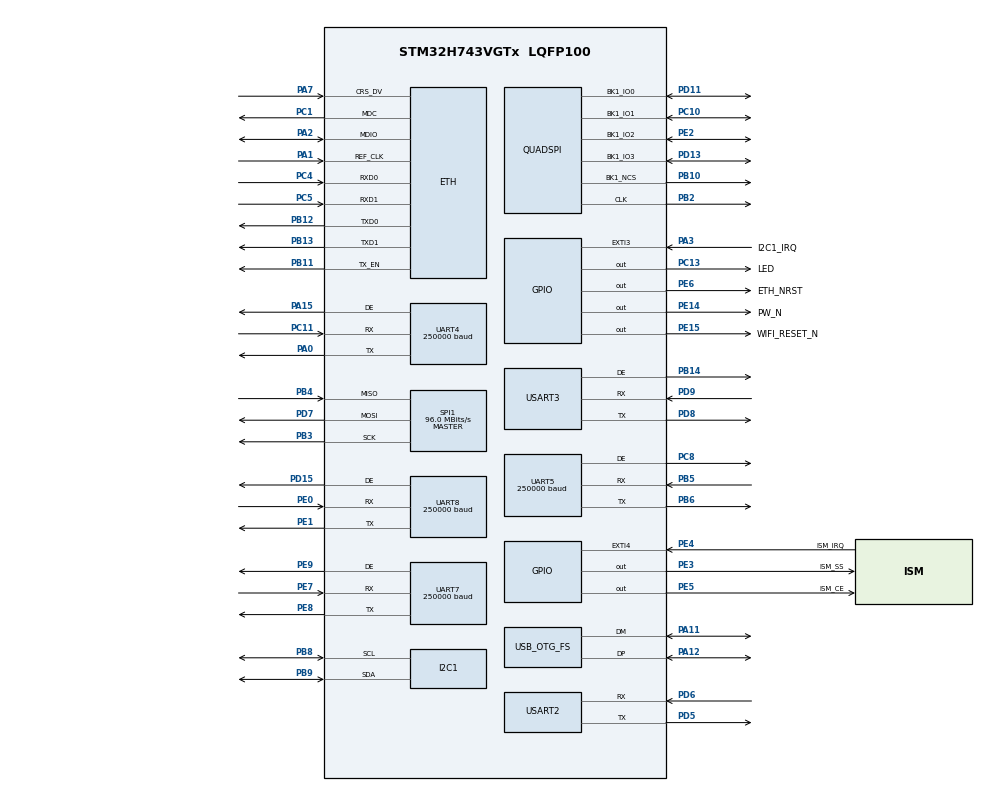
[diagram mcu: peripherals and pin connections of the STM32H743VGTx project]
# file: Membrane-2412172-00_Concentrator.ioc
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Dma.Request0=UART4_TX
Dma.Request1=UART5_TX
Dma.Request2=UART7_TX
Dma.Request3=UART8_TX
Dma.Request4=USART2_TX
Dma.UART4_TX.0.Direction=DMA_MEMORY_TO_PERIPH
Dma.UART4_TX.0.EventEnable=DISABLE
Dma.UART4_TX.0.FIFOMode=DMA_FIFOMODE_DISABLE
Dma.UART4_TX.0.Instance=DMA1_Stream0
Dma.UART4_TX.0.MemDataAlignment=DMA_MDATAALIGN_BYTE
Dma.UART4_TX.0.MemInc=DMA_MINC_ENABLE
Dma.UART4_TX.0.Mode=DMA_NORMAL
Dma.UART4_TX.0.PeriphDataAlignment=DMA_PDATAALIGN_BYTE
Dma.UART4_TX.0.PeriphInc=DMA_PINC_DISABLE
Dma.UART4_TX.0.Polarity=HAL_DMAMUX_REQ_GEN_RISING
Dma.UART4_TX.0.Priority=DMA_PRIORITY_LOW
Dma.UART4_TX.0.RequestNumber=1
Dma.UART4_TX.0.SignalID=NONE
Dma.UART4_TX.0.SyncEnable=DISABLE
Dma.UART4_TX.0.SyncPolarity=HAL_DMAMUX_SYNC_NO_EVENT
Dma.UART4_TX.0.SyncRequestNumber=1
Dma.UART4_TX.0.SyncSignalID=NONE
Dma.UART5_TX.1.Direction=DMA_MEMORY_TO_PERIPH
Dma.UART5_TX.1.EventEnable=DISABLE
Dma.UART5_TX.1.FIFOMode=DMA_FIFOMODE_DISABLE
Dma.UART5_TX.1.Instance=DMA1_Stream1
Dma.UART5_TX.1.MemDataAlignment=DMA_MDATAALIGN_BYTE
Dma.UART5_TX.1.MemInc=DMA_MINC_ENABLE
Dma.UART5_TX.1.Mode=DMA_NORMAL
Dma.UART5_TX.1.PeriphDataAlignment=DMA_PDATAALIGN_BYTE
Dma.UART5_TX.1.PeriphInc=DMA_PINC_DISABLE
Dma.UART5_TX.1.Polarity=HAL_DMAMUX_REQ_GEN_RISING
Dma.UART5_TX.1.Priority=DMA_PRIORITY_LOW
Dma.UART5_TX.1.RequestNumber=1
Dma.UART5_TX.1.SignalID=NONE
Dma.UART5_TX.1.SyncEnable=DISABLE
Dma.UART5_TX.1.SyncPolarity=HAL_DMAMUX_SYNC_NO_EVENT
Dma.UART5_TX.1.SyncRequestNumber=1
Dma.UART5_TX.1.SyncSignalID=NONE
Dma.UART7_TX.2.Direction=DMA_MEMORY_TO_PERIPH
Dma.UART7_TX.2.EventEnable=DISABLE
Dma.UART7_TX.2.FIFOMode=DMA_FIFOMODE_DISABLE
Dma.UART7_TX.2.Instance=DMA1_Stream2
Dma.UART7_TX.2.MemDataAlignment=DMA_MDATAALIGN_BYTE
Dma.UART7_TX.2.MemInc=DMA_MINC_ENABLE
Dma.UART7_TX.2.Mode=DMA_NORMAL
Dma.UART7_TX.2.PeriphDataAlignment=DMA_PDATAALIGN_BYTE
Dma.UART7_TX.2.PeriphInc=DMA_PINC_DISABLE
Dma.UART7_TX.2.Polarity=HAL_DMAMUX_REQ_GEN_RISING
Dma.UART7_TX.2.Priority=DMA_PRIORITY_LOW
Dma.UART7_TX.2.RequestNumber=1
Dma.UART7_TX.2.SignalID=NONE
Dma.UART7_TX.2.SyncEnable=DISABLE
Dma.UART7_TX.2.SyncPolarity=HAL_DMAMUX_SYNC_NO_EVENT
Dma.UART7_TX.2.SyncRequestNumber=1
Dma.UART7_TX.2.SyncSignalID=NONE
Dma.UART8_TX.3.Direction=DMA_MEMORY_TO_PERIPH
Dma.UART8_TX.3.EventEnable=DISABLE
Dma.UART8_TX.3.FIFOMode=DMA_FIFOMODE_DISABLE
Dma.UART8_TX.3.Instance=DMA1_Stream3
Dma.UART8_TX.3.MemDataAlignment=DMA_MDATAALIGN_BYTE
Dma.UART8_TX.3.MemInc=DMA_MINC_ENABLE
Dma.UART8_TX.3.Mode=DMA_NORMAL
Dma.UART8_TX.3.PeriphDataAlignment=DMA_PDATAALIGN_BYTE
Dma.UART8_TX.3.PeriphInc=DMA_PINC_DISABLE
Dma.UART8_TX.3.Polarity=HAL_DMAMUX_REQ_GEN_RISING
Dma.UART8_TX.3.Priority=DMA_PRIORITY_LOW
Dma.UART8_TX.3.RequestNumber=1
Dma.UART8_TX.3.SignalID=NONE
Dma.UART8_TX.3.SyncEnable=DISABLE
Dma.UART8_TX.3.SyncPolarity=HAL_DMAMUX_SYNC_NO_EVENT
Dma.UART8_TX.3.SyncRequestNumber=1
Dma.UART8_TX.3.SyncSignalID=NONE
Dma.USART2_TX.4.Direction=DMA_MEMORY_TO_PERIPH
Dma.USART2_TX.4.EventEnable=DISABLE
Dma.USART2_TX.4.FIFOMode=DMA_FIFOMODE_DISABLE
Dma.USART2_TX.4.Instance=DMA1_Stream4
Dma.USART2_TX.4.MemDataAlignment=DMA_MDATAALIGN_BYTE
Dma.USART2_TX.4.MemInc=DMA_MINC_ENABLE
Dma.USART2_TX.4.Mode=DMA_NORMAL
Dma.USART2_TX.4.PeriphDataAlignment=DMA_PDATAALIGN_BYTE
Dma.USART2_TX.4.PeriphInc=DMA_PINC_DISABLE
Dma.USART2_TX.4.Polarity=HAL_DMAMUX_REQ_GEN_RISING
Dma.USART2_TX.4.Priority=DMA_PRIORITY_LOW
Dma.USART2_TX.4.RequestNumber=1
Dma.USART2_TX.4.SignalID=NONE
Dma.USART2_TX.4.SyncEnable=DISABLE
Dma.USART2_TX.4.SyncPolarity=HAL_DMAMUX_SYNC_NO_EVENT
Dma.USART2_TX.4.SyncRequestNumber=1
Dma.USART2_TX.4.SyncSignalID=NONE
ETH.MediaInterface=HAL_ETH_RMII_MODE
I2C1.Timing=0x307075B1
Mcu.Family=STM32H7
Mcu.Name=STM32H743VGTx
Mcu.Package=LQFP100
NVIC.DMA1_Stream0_IRQn=true\:0\:0\:false\:false\:true\:false\:true\:true
NVIC.DMA1_Stream1_IRQn=true\:0\:0\:false\:false\:true\:false\:true\:true
NVIC.DMA1_Stream2_IRQn=true\:0\:0\:false\:false\:true\:false\:true\:true
NVIC.DMA1_Stream3_IRQn=true\:0\:0\:false\:false\:true\:false\:true\:true
NVIC.DMA1_Stream4_IRQn=true\:0\:0\:false\:false\:true\:false\:true\:true
NVIC.OTG_FS_IRQn=true\:0\:0\:false\:false\:true\:false\:true\:true
NVIC.PriorityGroup=NVIC_PRIORITYGROUP_4
NVIC.UART4_IRQn=true\:0\:0\:false\:false\:true\:true\:true\:true
NVIC.UART5_IRQn=true\:0\:0\:false\:false\:true\:true\:true\:true
NVIC.UART7_IRQn=true\:0\:0\:false\:false\:true\:true\:true\:true
NVIC.UART8_IRQn=true\:0\:0\:false\:false\:true\:true\:true\:true
NVIC.USART2_IRQn=true\:0\:0\:false\:false\:true\:true\:true\:true
PA0.Mode=Asynchronous
PA0.Signal=UART4_TX
PA1.GPIO_Speed=GPIO_SPEED_FREQ_VERY_HIGH
PA1.Mode=RMII
PA1.Signal=ETH_REF_CLK
PA11.Mode=Device_Only
PA11.Signal=USB_OTG_FS_DM
PA12.Mode=Device_Only
PA12.Signal=USB_OTG_FS_DP
PA13\ (JTMS/SWDIO).Mode=Serial_Wire
PA13\ (JTMS/SWDIO).Signal=DEBUG_JTMS-SWDIO
PA14\ (JTCK/SWCLK).Mode=Serial_Wire
PA14\ (JTCK/SWCLK).Signal=DEBUG_JTCK-SWCLK
PA15\ (JTDI).Mode=Hardware Flow Control (RS485)
PA15\ (JTDI).Signal=UART4_DE
PA2.GPIO_Speed=GPIO_SPEED_FREQ_VERY_HIGH
PA2.Mode=RMII
PA2.Signal=ETH_MDIO
PA3.GPIO_Label=I2C1_IRQ
PA3.Signal=GPXTI3
PA7.GPIO_Speed=GPIO_SPEED_FREQ_VERY_HIGH
PA7.Mode=RMII
PA7.Signal=ETH_CRS_DV
PB10.GPIO_Speed=GPIO_SPEED_FREQ_VERY_HIGH
PB10.Mode=Single Bank 1
PB10.Signal=QUADSPI_BK1_NCS
PB11.GPIO_Speed=GPIO_SPEED_FREQ_VERY_HIGH
PB11.Mode=RMII
PB11.Signal=ETH_TX_EN
PB12.GPIO_Speed=GPIO_SPEED_FREQ_VERY_HIGH
PB12.Mode=RMII
PB12.Signal=ETH_TXD0
PB13.GPIO_Speed=GPIO_SPEED_FREQ_VERY_HIGH
PB13.Mode=RMII
PB13.Signal=ETH_TXD1
PB14.Mode=Hardware Flow Control (RS485)
PB14.Signal=USART3_DE
PB2.GPIO_Speed=GPIO_SPEED_FREQ_VERY_HIGH
PB2.Mode=Single Bank 1
PB2.Signal=QUADSPI_CLK
PB3\ (JTDO/TRACESWO).Mode=Full_Duplex_Master
PB3\ (JTDO/TRACESWO).Signal=SPI1_SCK
PB4\ (NJTRST).Mode=Full_Duplex_Master
PB4\ (NJTRST).Signal=SPI1_MISO
PB5.Mode=Asynchronous
PB5.Signal=UART5_RX
PB6.Mode=Asynchronous
PB6.Signal=UART5_TX
PB8.Mode=I2C
PB8.Signal=I2C1_SCL
PB9.Mode=I2C
PB9.Signal=I2C1_SDA
PC1.GPIO_Speed=GPIO_SPEED_FREQ_VERY_HIGH
PC1.Mode=RMII
PC1.Signal=ETH_MDC
PC10.GPIO_Speed=GPIO_SPEED_FREQ_VERY_HIGH
PC10.Mode=Single Bank 1
PC10.Signal=QUADSPI_BK1_IO1
PC11.Mode=Asynchronous
PC11.Signal=UART4_RX
PC13.GPIO_Label=LED
PC13.Signal=GPIO_Output
PC4.GPIO_Speed=GPIO_SPEED_FREQ_VERY_HIGH
PC4.Mode=RMII
PC4.Signal=ETH_RXD0
PC5.GPIO_Speed=GPIO_SPEED_FREQ_VERY_HIGH
PC5.Mode=RMII
PC5.Signal=ETH_RXD1
PC8.Mode=Hardware Flow Control (RS485)
PC8.Signal=UART5_DE
PD11.GPIO_Speed=GPIO_SPEED_FREQ_VERY_HIGH
PD11.Mode=Single Bank 1
PD11.Signal=QUADSPI_BK1_IO0
PD13.GPIO_Speed=GPIO_SPEED_FREQ_VERY_HIGH
PD13.Mode=Single Bank 1
PD13.Signal=QUADSPI_BK1_IO3
PD15.Mode=Hardware Flow Control (RS485)
PD15.Signal=UART8_DE
PD5.GPIO_PuPd=GPIO_PULLUP
PD5.GPIO_Speed=GPIO_SPEED_FREQ_HIGH
PD5.Mode=Asynchronous
PD5.Signal=USART2_TX
PD6.GPIO_PuPd=GPIO_PULLUP
PD6.GPIO_Speed=GPIO_SPEED_FREQ_HIGH
PD6.Mode=Asynchronous
PD6.Signal=USART2_RX
PD7.Mode=Full_Duplex_Master
PD7.Signal=SPI1_MOSI
PD8.Mode=Asynchronous
PD8.Signal=USART3_TX
PD9.Mode=Asynchronous
PD9.Signal=USART3_RX
PE0.Mode=Asynchronous
PE0.Signal=UART8_RX
PE1.Mode=Asynchronous
PE1.Signal=UART8_TX
PE14.GPIO_Label=PW_N
PE14.PinState=GPIO_PIN_SET
PE14.Signal=GPIO_Output
PE15.GPIO_Label=WIFI_RESET_N
PE15.GPIO_ModeDefaultOutputPP=GPIO_MODE_OUTPUT_OD
PE15.GPIO_PuPd=GPIO_NOPULL
PE15.PinState=GPIO_PIN_SET
PE15.Signal=GPIO_Output
PE2.GPIO_Speed=GPIO_SPEED_FREQ_VERY_HIGH
PE2.Mode=Single Bank 1
PE2.Signal=QUADSPI_BK1_IO2
PE3.GPIO_Label=ISM_SS
PE3.PinState=GPIO_PIN_SET
PE3.Signal=GPIO_Output
PE4.GPIO_Label=ISM_IRQ
PE4.Signal=GPXTI4
PE5.GPIO_Label=ISM_CE
PE5.PinState=GPIO_PIN_SET
PE5.Signal=GPIO_Output
PE6.GPIO_Label=ETH_NRST
PE6.PinState=GPIO_PIN_SET
PE6.Signal=GPIO_Output
PE7.Mode=Asynchronous
PE7.Signal=UART7_RX
PE8.Mode=Asynchronous
PE8.Signal=UART7_TX
PE9.Mode=Hardware Flow Control (RS485)
PE9.Signal=UART7_DE
ProjectManager.HeapSize=0x200
ProjectManager.StackSize=0x400
ProjectManager.TargetToolchain=STM32CubeIDE
QUADSPI.ClockPrescaler=1
QUADSPI.FlashSize=23
RCC.ADCFreq_Value=100000000
RCC.APB1Freq_Value=120000000
RCC.APB2Freq_Value=120000000
RCC.APB3Freq_Value=120000000
RCC.APB4Freq_Value=120000000
RCC.CortexFreq_Value=480000000
RCC.D1PPRE=RCC_APB3_DIV2
RCC.D2PPRE1=RCC_APB1_DIV2
RCC.D2PPRE2=RCC_APB2_DIV2
RCC.D3PPRE=RCC_APB4_DIV2
RCC.DIVM1=4
RCC.DIVN1=60
RCC.DIVN2=100
RCC.DIVQ1=5
RCC.DIVR2=4
RCC.HCLKFreq_Value=240000000
RCC.HPRE=RCC_HCLK_DIV2
RCC.PLL2FRACN=0
RCC.PLL3FRACN=0
RCC.PLLFRACN=0
RCC.QSPICLockSelection=RCC_QSPICLKSOURCE_PLL2
RCC.SYSCLKFreq_VALUE=480000000
RCC.SYSCLKSource=RCC_SYSCLKSOURCE_PLLCLK
RCC.USART234578CLockSelection=RCC_USART234578CLKSOURCE_CSI
RCC.USBCLockSelection=RCC_USBCLKSOURCE_HSI48
RCC.USBFreq_Value=48000000
SPI1.BaudRatePrescaler=SPI_BAUDRATEPRESCALER_2
SPI1.CalculateBaudRate=96.0 MBits/s
SPI1.Direction=SPI_DIRECTION_2LINES
SPI1.Mode=SPI_MODE_MASTER
SPI1.VirtualType=VM_MASTER
UART4.BaudRate=250000
UART5.BaudRate=250000
UART7.BaudRate=250000
UART8.BaudRate=250000
USART2.DataInvertParam=ADVFEATURE_DATAINV_DISABLE
USART2.FIFOMode=FIFOMODE_ENABLE
USART2.RXFIFOThreshold=RXFIFO_THRESHOLD_HALFFULL
USART2.SwapParam=ADVFEATURE_SWAP_ENABLE
USART2.TXFIFOThreshold=TXFIFO_THRESHOLD_HALFFULL
USART2.VirtualMode-Asynchronous=VM_ASYNC
USART3.VirtualMode-Asynchronous=VM_ASYNC
USART3.VirtualMode-Hardware\ Flow\ Control\ (RS485)=VM_ASYNC
USB_DEVICE.CLASS_NAME_FS=CDC
USB_DEVICE.VirtualMode-CDC_FS=Cdc
USB_DEVICE.VirtualModeFS=Cdc_FS
USB_OTG_FS.VirtualMode=Device_Only
VP_CRC_VS_CRC.Mode=CRC_Activate
VP_USB_DEVICE_VS_USB_DEVICE_CDC_FS.Mode=CDC_FS
board=custom

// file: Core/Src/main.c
/* USER CODE BEGIN Header */
/**
  ******************************************************************************
  * @file           : main.c
  * @brief          : Main program body
  ******************************************************************************
  * @attention
  *
  * Copyright (c) 2024 STMicroelectronics.
  * All rights reserved.
  *
  * This software is licensed under terms that can be found in the LICENSE file
  * in the root directory of this software component.
  * If no LICENSE file comes with this software, it is provided AS-IS.
  *
  ******************************************************************************
  */
/* USER CODE END Header */
#include "main.h"
#include "string.h"
#include "usb_device.h"

#if defined ( __ICCARM__ ) /*!< IAR Compiler */
#pragma location=0x30000000
ETH_DMADescTypeDef  DMARxDscrTab[ETH_RX_DESC_CNT]; /* Ethernet Rx DMA Descriptors */
#pragma location=0x30000080
ETH_DMADescTypeDef  DMATxDscrTab[ETH_TX_DESC_CNT]; /* Ethernet Tx DMA Descriptors */

#elif defined ( __CC_ARM )  /* MDK ARM Compiler */

__attribute__((at(0x30000000))) ETH_DMADescTypeDef  DMARxDscrTab[ETH_RX_DESC_CNT]; /* Ethernet Rx DMA Descriptors */
__attribute__((at(0x30000080))) ETH_DMADescTypeDef  DMATxDscrTab[ETH_TX_DESC_CNT]; /* Ethernet Tx DMA Descriptors */

#elif defined ( __GNUC__ ) /* GNU Compiler */

ETH_DMADescTypeDef DMARxDscrTab[ETH_RX_DESC_CNT] __attribute__((section(".RxDecripSection"))); /* Ethernet Rx DMA Descriptors */
ETH_DMADescTypeDef DMATxDscrTab[ETH_TX_DESC_CNT] __attribute__((section(".TxDecripSection")));   /* Ethernet Tx DMA Descriptors */
#endif

ETH_TxPacketConfig TxConfig;

CRC_HandleTypeDef hcrc;

ETH_HandleTypeDef heth;

I2C_HandleTypeDef hi2c1;

QSPI_HandleTypeDef hqspi;

SPI_HandleTypeDef hspi1;

UART_HandleTypeDef huart4;
UART_HandleTypeDef huart5;
UART_HandleTypeDef huart7;
UART_HandleTypeDef huart8;
UART_HandleTypeDef huart2;
UART_HandleTypeDef huart3;
DMA_HandleTypeDef hdma_uart4_tx;
DMA_HandleTypeDef hdma_uart5_tx;
DMA_HandleTypeDef hdma_uart7_tx;
DMA_HandleTypeDef hdma_uart8_tx;
DMA_HandleTypeDef hdma_usart2_tx;

void SystemClock_Config(void);
static void MX_GPIO_Init(void);
static void MX_DMA_Init(void);
static void MX_I2C1_Init(void);
static void MX_QUADSPI_Init(void);
static void MX_UART4_Init(void);
static void MX_UART5_Init(void);
static void MX_UART7_Init(void);
static void MX_UART8_Init(void);
static void MX_USART2_UART_Init(void);
static void MX_USART3_UART_Init(void);
static void MX_SPI1_Init(void);
static void MX_CRC_Init(void);
static void MX_ETH_Init(void);

int main(void)
{

  /* MCU Configuration--------------------------------------------------------*/

  /* Reset of all peripherals, Initializes the Flash interface and the Systick. */
  HAL_Init();

  /* Configure the system clock */
  SystemClock_Config();

  /* USER CODE BEGIN SysInit */
  A_init_mem();

  /* USER CODE END SysInit */

  /* Initialize all configured peripherals */
  MX_GPIO_Init();
  MX_DMA_Init();
  MX_I2C1_Init();
  MX_QUADSPI_Init();
  MX_UART4_Init();
  MX_UART5_Init();
  MX_UART7_Init();
  MX_UART8_Init();
  MX_USART2_UART_Init();
  MX_USART3_UART_Init();
  MX_SPI1_Init();
  MX_CRC_Init();
  MX_ETH_Init();
  MX_USB_DEVICE_Init();
  /* USER CODE BEGIN 2 */
  A_start();

  /* USER CODE END 2 */

  /* Infinite loop */
  while (1)
  {

  }
}

void SystemClock_Config(void)
{
  RCC_OscInitTypeDef RCC_OscInitStruct = {0};
  RCC_ClkInitTypeDef RCC_ClkInitStruct = {0};

  /** Supply configuration update enable
  */
  HAL_PWREx_ConfigSupply(PWR_LDO_SUPPLY);

  /** Configure the main internal regulator output voltage
  */
  __HAL_PWR_VOLTAGESCALING_CONFIG(PWR_REGULATOR_VOLTAGE_SCALE1);

  while(!__HAL_PWR_GET_FLAG(PWR_FLAG_VOSRDY)) {}

  __HAL_RCC_SYSCFG_CLK_ENABLE();
  __HAL_PWR_VOLTAGESCALING_CONFIG(PWR_REGULATOR_VOLTAGE_SCALE0);

  while(!__HAL_PWR_GET_FLAG(PWR_FLAG_VOSRDY)) {}

  /** Initializes the RCC Oscillators according to the specified parameters
  * in the RCC_OscInitTypeDef structure.
  */
  RCC_OscInitStruct.OscillatorType = RCC_OSCILLATORTYPE_HSI48|RCC_OSCILLATORTYPE_CSI
                              |RCC_OSCILLATORTYPE_HSI;
  RCC_OscInitStruct.HSIState = RCC_HSI_DIV1;
  RCC_OscInitStruct.HSICalibrationValue = RCC_HSICALIBRATION_DEFAULT;
  RCC_OscInitStruct.HSI48State = RCC_HSI48_ON;
  RCC_OscInitStruct.CSIState = RCC_CSI_ON;
  RCC_OscInitStruct.CSICalibrationValue = RCC_CSICALIBRATION_DEFAULT;
  RCC_OscInitStruct.PLL.PLLState = RCC_PLL_ON;
  RCC_OscInitStruct.PLL.PLLSource = RCC_PLLSOURCE_HSI;
  RCC_OscInitStruct.PLL.PLLM = 4;
  RCC_OscInitStruct.PLL.PLLN = 60;
  RCC_OscInitStruct.PLL.PLLP = 2;
  RCC_OscInitStruct.PLL.PLLQ = 5;
  RCC_OscInitStruct.PLL.PLLR = 2;
  RCC_OscInitStruct.PLL.PLLRGE = RCC_PLL1VCIRANGE_3;
  RCC_OscInitStruct.PLL.PLLVCOSEL = RCC_PLL1VCOWIDE;
  RCC_OscInitStruct.PLL.PLLFRACN = 0;
  if (HAL_RCC_OscConfig(&RCC_OscInitStruct) != HAL_OK)
  {
    Error_Handler();
  }

  /** Initializes the CPU, AHB and APB buses clocks
  */
  RCC_ClkInitStruct.ClockType = RCC_CLOCKTYPE_HCLK|RCC_CLOCKTYPE_SYSCLK
                              |RCC_CLOCKTYPE_PCLK1|RCC_CLOCKTYPE_PCLK2
                              |RCC_CLOCKTYPE_D3PCLK1|RCC_CLOCKTYPE_D1PCLK1;
  RCC_ClkInitStruct.SYSCLKSource = RCC_SYSCLKSOURCE_PLLCLK;
  RCC_ClkInitStruct.SYSCLKDivider = RCC_SYSCLK_DIV1;
  RCC_ClkInitStruct.AHBCLKDivider = RCC_HCLK_DIV2;
  RCC_ClkInitStruct.APB3CLKDivider = RCC_APB3_DIV2;
  RCC_ClkInitStruct.APB1CLKDivider = RCC_APB1_DIV2;
  RCC_ClkInitStruct.APB2CLKDivider = RCC_APB2_DIV2;
  RCC_ClkInitStruct.APB4CLKDivider = RCC_APB4_DIV2;

  if (HAL_RCC_ClockConfig(&RCC_ClkInitStruct, FLASH_LATENCY_4) != HAL_OK)
  {
    Error_Handler();
  }
}

static void MX_CRC_Init(void)
{

  hcrc.Instance = CRC;
  hcrc.Init.DefaultPolynomialUse = DEFAULT_POLYNOMIAL_ENABLE;
  hcrc.Init.DefaultInitValueUse = DEFAULT_INIT_VALUE_ENABLE;
  hcrc.Init.InputDataInversionMode = CRC_INPUTDATA_INVERSION_NONE;
  hcrc.Init.OutputDataInversionMode = CRC_OUTPUTDATA_INVERSION_DISABLE;
  hcrc.InputDataFormat = CRC_INPUTDATA_FORMAT_BYTES;
  if (HAL_CRC_Init(&hcrc) != HAL_OK)
  {
    Error_Handler();
  }

}

static void MX_ETH_Init(void)
{

  /* USER CODE BEGIN ETH_Init 0 */
#ifdef	NETWORKING_ENABLED

  /* USER CODE END ETH_Init 0 */

   static uint8_t MACAddr[6];

  heth.Instance = ETH;
  MACAddr[0] = 0x00;
  MACAddr[1] = 0x80;
  MACAddr[2] = 0xE1;
  MACAddr[3] = 0x00;
  MACAddr[4] = 0x00;
  MACAddr[5] = 0x00;
  heth.Init.MACAddr = &MACAddr[0];
  heth.Init.MediaInterface = HAL_ETH_RMII_MODE;
  heth.Init.TxDesc = DMATxDscrTab;
  heth.Init.RxDesc = DMARxDscrTab;
  heth.Init.RxBuffLen = 1524;

  if (HAL_ETH_Init(&heth) != HAL_OK)
  {
    Error_Handler();
  }

  memset(&TxConfig, 0 , sizeof(ETH_TxPacketConfig));
  TxConfig.Attributes = ETH_TX_PACKETS_FEATURES_CSUM | ETH_TX_PACKETS_FEATURES_CRCPAD;
  TxConfig.ChecksumCtrl = ETH_CHECKSUM_IPHDR_PAYLOAD_INSERT_PHDR_CALC;
  TxConfig.CRCPadCtrl = ETH_CRC_PAD_INSERT;
  /* USER CODE BEGIN ETH_Init 2 */
#endif
  /* USER CODE END ETH_Init 2 */

}

static void MX_I2C1_Init(void)
{

  hi2c1.Instance = I2C1;
  hi2c1.Init.Timing = 0x307075B1;
  hi2c1.Init.OwnAddress1 = 0;
  hi2c1.Init.AddressingMode = I2C_ADDRESSINGMODE_7BIT;
  hi2c1.Init.DualAddressMode = I2C_DUALADDRESS_DISABLE;
  hi2c1.Init.OwnAddress2 = 0;
  hi2c1.Init.OwnAddress2Masks = I2C_OA2_NOMASK;
  hi2c1.Init.GeneralCallMode = I2C_GENERALCALL_DISABLE;
  hi2c1.Init.NoStretchMode = I2C_NOSTRETCH_DISABLE;
  if (HAL_I2C_Init(&hi2c1) != HAL_OK)
  {
    Error_Handler();
  }

  /** Configure Analogue filter
  */
  if (HAL_I2CEx_ConfigAnalogFilter(&hi2c1, I2C_ANALOGFILTER_ENABLE) != HAL_OK)
  {
    Error_Handler();
  }

  /** Configure Digital filter
  */
  if (HAL_I2CEx_ConfigDigitalFilter(&hi2c1, 0) != HAL_OK)
  {
    Error_Handler();
  }

}

static void MX_QUADSPI_Init(void)
{

  /* QUADSPI parameter configuration*/
  hqspi.Instance = QUADSPI;
  hqspi.Init.ClockPrescaler = 1;
  hqspi.Init.FifoThreshold = 1;
  hqspi.Init.SampleShifting = QSPI_SAMPLE_SHIFTING_NONE;
  hqspi.Init.FlashSize = 23;
  hqspi.Init.ChipSelectHighTime = QSPI_CS_HIGH_TIME_1_CYCLE;
  hqspi.Init.ClockMode = QSPI_CLOCK_MODE_0;
  hqspi.Init.FlashID = QSPI_FLASH_ID_1;
  hqspi.Init.DualFlash = QSPI_DUALFLASH_DISABLE;
  if (HAL_QSPI_Init(&hqspi) != HAL_OK)
  {
    Error_Handler();
  }

}

static void MX_SPI1_Init(void)
{

  /* SPI1 parameter configuration*/
  hspi1.Instance = SPI1;
  hspi1.Init.Mode = SPI_MODE_MASTER;
  hspi1.Init.Direction = SPI_DIRECTION_2LINES;
  hspi1.Init.DataSize = SPI_DATASIZE_4BIT;
  hspi1.Init.CLKPolarity = SPI_POLARITY_LOW;
  hspi1.Init.CLKPhase = SPI_PHASE_1EDGE;
  hspi1.Init.NSS = SPI_NSS_SOFT;
  hspi1.Init.BaudRatePrescaler = SPI_BAUDRATEPRESCALER_2;
  hspi1.Init.FirstBit = SPI_FIRSTBIT_MSB;
  hspi1.Init.TIMode = SPI_TIMODE_DISABLE;
  hspi1.Init.CRCCalculation = SPI_CRCCALCULATION_DISABLE;
  hspi1.Init.CRCPolynomial = 0x0;
  hspi1.Init.NSSPMode = SPI_NSS_PULSE_ENABLE;
  hspi1.Init.NSSPolarity = SPI_NSS_POLARITY_LOW;
  hspi1.Init.FifoThreshold = SPI_FIFO_THRESHOLD_01DATA;
  hspi1.Init.TxCRCInitializationPattern = SPI_CRC_INITIALIZATION_ALL_ZERO_PATTERN;
  hspi1.Init.RxCRCInitializationPattern = SPI_CRC_INITIALIZATION_ALL_ZERO_PATTERN;
  hspi1.Init.MasterSSIdleness = SPI_MASTER_SS_IDLENESS_00CYCLE;
  hspi1.Init.MasterInterDataIdleness = SPI_MASTER_INTERDATA_IDLENESS_00CYCLE;
  hspi1.Init.MasterReceiverAutoSusp = SPI_MASTER_RX_AUTOSUSP_DISABLE;
  hspi1.Init.MasterKeepIOState = SPI_MASTER_KEEP_IO_STATE_DISABLE;
  hspi1.Init.IOSwap = SPI_IO_SWAP_DISABLE;
  if (HAL_SPI_Init(&hspi1) != HAL_OK)
  {
    Error_Handler();
  }

}

static void MX_UART4_Init(void)
{

  huart4.Instance = UART4;
  huart4.Init.BaudRate = 250000;
  huart4.Init.WordLength = UART_WORDLENGTH_8B;
  huart4.Init.StopBits = UART_STOPBITS_1;
  huart4.Init.Parity = UART_PARITY_NONE;
  huart4.Init.Mode = UART_MODE_TX_RX;
  huart4.Init.HwFlowCtl = UART_HWCONTROL_NONE;
  huart4.Init.OverSampling = UART_OVERSAMPLING_16;
  huart4.Init.OneBitSampling = UART_ONE_BIT_SAMPLE_DISABLE;
  huart4.Init.ClockPrescaler = UART_PRESCALER_DIV1;
  huart4.AdvancedInit.AdvFeatureInit = UART_ADVFEATURE_NO_INIT;
  if (HAL_RS485Ex_Init(&huart4, UART_DE_POLARITY_HIGH, 0, 0) != HAL_OK)
  {
    Error_Handler();
  }
  if (HAL_UARTEx_SetTxFifoThreshold(&huart4, UART_TXFIFO_THRESHOLD_1_8) != HAL_OK)
  {
    Error_Handler();
  }
  if (HAL_UARTEx_SetRxFifoThreshold(&huart4, UART_RXFIFO_THRESHOLD_1_8) != HAL_OK)
  {
    Error_Handler();
  }
  if (HAL_UARTEx_DisableFifoMode(&huart4) != HAL_OK)
  {
    Error_Handler();
  }

}

static void MX_UART5_Init(void)
{

  huart5.Instance = UART5;
  huart5.Init.BaudRate = 250000;
  huart5.Init.WordLength = UART_WORDLENGTH_8B;
  huart5.Init.StopBits = UART_STOPBITS_1;
  huart5.Init.Parity = UART_PARITY_NONE;
  huart5.Init.Mode = UART_MODE_TX_RX;
  huart5.Init.HwFlowCtl = UART_HWCONTROL_NONE;
  huart5.Init.OverSampling = UART_OVERSAMPLING_16;
  huart5.Init.OneBitSampling = UART_ONE_BIT_SAMPLE_DISABLE;
  huart5.Init.ClockPrescaler = UART_PRESCALER_DIV1;
  huart5.AdvancedInit.AdvFeatureInit = UART_ADVFEATURE_NO_INIT;
  if (HAL_RS485Ex_Init(&huart5, UART_DE_POLARITY_HIGH, 0, 0) != HAL_OK)
  {
    Error_Handler();
  }
  if (HAL_UARTEx_SetTxFifoThreshold(&huart5, UART_TXFIFO_THRESHOLD_1_8) != HAL_OK)
  {
    Error_Handler();
  }
  if (HAL_UARTEx_SetRxFifoThreshold(&huart5, UART_RXFIFO_THRESHOLD_1_8) != HAL_OK)
  {
    Error_Handler();
  }
  if (HAL_UARTEx_DisableFifoMode(&huart5) != HAL_OK)
  {
    Error_Handler();
  }

}

static void MX_UART7_Init(void)
{

  huart7.Instance = UART7;
  huart7.Init.BaudRate = 250000;
  huart7.Init.WordLength = UART_WORDLENGTH_8B;
  huart7.Init.StopBits = UART_STOPBITS_1;
  huart7.Init.Parity = UART_PARITY_NONE;
  huart7.Init.Mode = UART_MODE_TX_RX;
  huart7.Init.HwFlowCtl = UART_HWCONTROL_NONE;
  huart7.Init.OverSampling = UART_OVERSAMPLING_16;
  huart7.Init.OneBitSampling = UART_ONE_BIT_SAMPLE_DISABLE;
  huart7.Init.ClockPrescaler = UART_PRESCALER_DIV1;
  huart7.AdvancedInit.AdvFeatureInit = UART_ADVFEATURE_NO_INIT;
  if (HAL_RS485Ex_Init(&huart7, UART_DE_POLARITY_HIGH, 0, 0) != HAL_OK)
  {
    Error_Handler();
  }
  if (HAL_UARTEx_SetTxFifoThreshold(&huart7, UART_TXFIFO_THRESHOLD_1_8) != HAL_OK)
  {
    Error_Handler();
  }
  if (HAL_UARTEx_SetRxFifoThreshold(&huart7, UART_RXFIFO_THRESHOLD_1_8) != HAL_OK)
  {
    Error_Handler();
  }
  if (HAL_UARTEx_DisableFifoMode(&huart7) != HAL_OK)
  {
    Error_Handler();
  }

}

static void MX_UART8_Init(void)
{

  huart8.Instance = UART8;
  huart8.Init.BaudRate = 250000;
  huart8.Init.WordLength = UART_WORDLENGTH_8B;
  huart8.Init.StopBits = UART_STOPBITS_1;
  huart8.Init.Parity = UART_PARITY_NONE;
  huart8.Init.Mode = UART_MODE_TX_RX;
  huart8.Init.HwFlowCtl = UART_HWCONTROL_NONE;
  huart8.Init.OverSampling = UART_OVERSAMPLING_16;
  huart8.Init.OneBitSampling = UART_ONE_BIT_SAMPLE_DISABLE;
  huart8.Init.ClockPrescaler = UART_PRESCALER_DIV1;
  huart8.AdvancedInit.AdvFeatureInit = UART_ADVFEATURE_NO_INIT;
  if (HAL_RS485Ex_Init(&huart8, UART_DE_POLARITY_HIGH, 0, 0) != HAL_OK)
  {
    Error_Handler();
  }
  if (HAL_UARTEx_SetTxFifoThreshold(&huart8, UART_TXFIFO_THRESHOLD_1_8) != HAL_OK)
  {
    Error_Handler();
  }
  if (HAL_UARTEx_SetRxFifoThreshold(&huart8, UART_RXFIFO_THRESHOLD_1_8) != HAL_OK)
  {
    Error_Handler();
  }
  if (HAL_UARTEx_DisableFifoMode(&huart8) != HAL_OK)
  {
    Error_Handler();
  }

}

static void MX_USART2_UART_Init(void)
{

  huart2.Instance = USART2;
  huart2.Init.BaudRate = 115200;
  huart2.Init.WordLength = UART_WORDLENGTH_8B;
  huart2.Init.StopBits = UART_STOPBITS_1;
  huart2.Init.Parity = UART_PARITY_NONE;
  huart2.Init.Mode = UART_MODE_TX_RX;
  huart2.Init.HwFlowCtl = UART_HWCONTROL_NONE;
  huart2.Init.OverSampling = UART_OVERSAMPLING_16;
  huart2.Init.OneBitSampling = UART_ONE_BIT_SAMPLE_DISABLE;
  huart2.Init.ClockPrescaler = UART_PRESCALER_DIV1;
  huart2.AdvancedInit.AdvFeatureInit = UART_ADVFEATURE_SWAP_INIT;
  huart2.AdvancedInit.Swap = UART_ADVFEATURE_SWAP_ENABLE;
  if (HAL_UART_Init(&huart2) != HAL_OK)
  {
    Error_Handler();
  }
  if (HAL_UARTEx_SetTxFifoThreshold(&huart2, UART_TXFIFO_THRESHOLD_1_2) != HAL_OK)
  {
    Error_Handler();
  }
  if (HAL_UARTEx_SetRxFifoThreshold(&huart2, UART_RXFIFO_THRESHOLD_1_2) != HAL_OK)
  {
    Error_Handler();
  }
  if (HAL_UARTEx_EnableFifoMode(&huart2) != HAL_OK)
  {
    Error_Handler();
  }

}

static void MX_USART3_UART_Init(void)
{

  huart3.Instance = USART3;
  huart3.Init.BaudRate = 115200;
  huart3.Init.WordLength = UART_WORDLENGTH_8B;
  huart3.Init.StopBits = UART_STOPBITS_1;
  huart3.Init.Parity = UART_PARITY_NONE;
  huart3.Init.Mode = UART_MODE_TX_RX;
  huart3.Init.HwFlowCtl = UART_HWCONTROL_NONE;
  huart3.Init.OverSampling = UART_OVERSAMPLING_16;
  huart3.Init.OneBitSampling = UART_ONE_BIT_SAMPLE_DISABLE;
  huart3.Init.ClockPrescaler = UART_PRESCALER_DIV1;
  huart3.AdvancedInit.AdvFeatureInit = UART_ADVFEATURE_NO_INIT;
  if (HAL_RS485Ex_Init(&huart3, UART_DE_POLARITY_HIGH, 0, 0) != HAL_OK)
  {
    Error_Handler();
  }
  if (HAL_UARTEx_SetTxFifoThreshold(&huart3, UART_TXFIFO_THRESHOLD_1_8) != HAL_OK)
  {
    Error_Handler();
  }
  if (HAL_UARTEx_SetRxFifoThreshold(&huart3, UART_RXFIFO_THRESHOLD_1_8) != HAL_OK)
  {
    Error_Handler();
  }
  if (HAL_UARTEx_DisableFifoMode(&huart3) != HAL_OK)
  {
    Error_Handler();
  }

}

static void MX_DMA_Init(void)
{

  /* DMA controller clock enable */
  __HAL_RCC_DMA1_CLK_ENABLE();

  /* DMA interrupt init */
  /* DMA1_Stream0_IRQn interrupt configuration */
  HAL_NVIC_SetPriority(DMA1_Stream0_IRQn, 0, 0);
  HAL_NVIC_EnableIRQ(DMA1_Stream0_IRQn);
  /* DMA1_Stream1_IRQn interrupt configuration */
  HAL_NVIC_SetPriority(DMA1_Stream1_IRQn, 0, 0);
  HAL_NVIC_EnableIRQ(DMA1_Stream1_IRQn);
  /* DMA1_Stream2_IRQn interrupt configuration */
  HAL_NVIC_SetPriority(DMA1_Stream2_IRQn, 0, 0);
  HAL_NVIC_EnableIRQ(DMA1_Stream2_IRQn);
  /* DMA1_Stream3_IRQn interrupt configuration */
  HAL_NVIC_SetPriority(DMA1_Stream3_IRQn, 0, 0);
  HAL_NVIC_EnableIRQ(DMA1_Stream3_IRQn);
  /* DMA1_Stream4_IRQn interrupt configuration */
  HAL_NVIC_SetPriority(DMA1_Stream4_IRQn, 0, 0);
  HAL_NVIC_EnableIRQ(DMA1_Stream4_IRQn);

}

static void MX_GPIO_Init(void)
{
  GPIO_InitTypeDef GPIO_InitStruct = {0};

  /* GPIO Ports Clock Enable */
  __HAL_RCC_GPIOE_CLK_ENABLE();
  __HAL_RCC_GPIOC_CLK_ENABLE();
  __HAL_RCC_GPIOA_CLK_ENABLE();
  __HAL_RCC_GPIOB_CLK_ENABLE();
  __HAL_RCC_GPIOD_CLK_ENABLE();

  /*Configure GPIO pin Output Level */
  HAL_GPIO_WritePin(GPIOE, ISM_SS_Pin|ISM_CE_Pin|ETH_NRST_Pin|PW_N_Pin
                          |WIFI_RESET_N_Pin, GPIO_PIN_SET);

  /*Configure GPIO pin Output Level */
  HAL_GPIO_WritePin(LED_GPIO_Port, LED_Pin, GPIO_PIN_RESET);

  /*Configure GPIO pins : ISM_SS_Pin ISM_CE_Pin ETH_NRST_Pin PW_N_Pin */
  GPIO_InitStruct.Pin = ISM_SS_Pin|ISM_CE_Pin|ETH_NRST_Pin|PW_N_Pin;
  GPIO_InitStruct.Mode = GPIO_MODE_OUTPUT_PP;
  GPIO_InitStruct.Pull = GPIO_NOPULL;
  GPIO_InitStruct.Speed = GPIO_SPEED_FREQ_LOW;
  HAL_GPIO_Init(GPIOE, &GPIO_InitStruct);

  /*Configure GPIO pin : ISM_IRQ_Pin */
  GPIO_InitStruct.Pin = ISM_IRQ_Pin;
  GPIO_InitStruct.Mode = GPIO_MODE_IT_RISING;
  GPIO_InitStruct.Pull = GPIO_NOPULL;
  HAL_GPIO_Init(ISM_IRQ_GPIO_Port, &GPIO_InitStruct);

  /*Configure GPIO pin : LED_Pin */
  GPIO_InitStruct.Pin = LED_Pin;
  GPIO_InitStruct.Mode = GPIO_MODE_OUTPUT_PP;
  GPIO_InitStruct.Pull = GPIO_NOPULL;
  GPIO_InitStruct.Speed = GPIO_SPEED_FREQ_LOW;
  HAL_GPIO_Init(LED_GPIO_Port, &GPIO_InitStruct);

  /*Configure GPIO pin : I2C1_IRQ_Pin */
  GPIO_InitStruct.Pin = I2C1_IRQ_Pin;
  GPIO_InitStruct.Mode = GPIO_MODE_IT_RISING;
  GPIO_InitStruct.Pull = GPIO_NOPULL;
  HAL_GPIO_Init(I2C1_IRQ_GPIO_Port, &GPIO_InitStruct);

  /*Configure GPIO pin : WIFI_RESET_N_Pin */
  GPIO_InitStruct.Pin = WIFI_RESET_N_Pin;
  GPIO_InitStruct.Mode = GPIO_MODE_OUTPUT_OD;
  GPIO_InitStruct.Pull = GPIO_NOPULL;
  GPIO_InitStruct.Speed = GPIO_SPEED_FREQ_LOW;
  HAL_GPIO_Init(WIFI_RESET_N_GPIO_Port, &GPIO_InitStruct);

}

void Error_Handler(void)
{
  __disable_irq();
  while (1)
  {
  }
}
